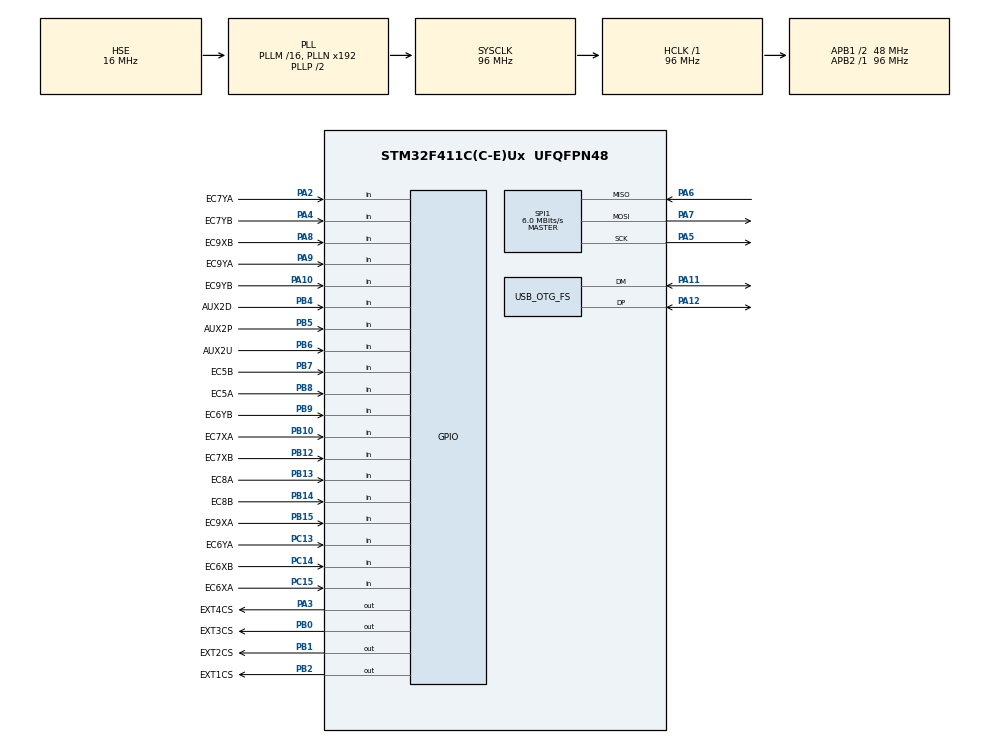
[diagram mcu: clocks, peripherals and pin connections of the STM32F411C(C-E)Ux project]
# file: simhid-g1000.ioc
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Mcu.Family=STM32F4
Mcu.Name=STM32F411C(C-E)Ux
Mcu.Package=UFQFPN48
NVIC.OTG_FS_IRQn=true\:0\:0\:false\:false\:true\:false\:true
NVIC.PriorityGroup=NVIC_PRIORITYGROUP_4
PA10.GPIO_Label=EC9YB
PA10.Signal=GPIO_Input
PA11.Mode=Device_Only
PA11.Signal=USB_OTG_FS_DM
PA12.Mode=Device_Only
PA12.Signal=USB_OTG_FS_DP
PA13.Mode=Serial_Wire
PA13.Signal=SYS_JTMS-SWDIO
PA14.Mode=Serial_Wire
PA14.Signal=SYS_JTCK-SWCLK
PA2.GPIO_Label=EC7YA
PA2.Signal=GPIO_Input
PA3.GPIO_Label=EXT4CS
PA3.PinState=GPIO_PIN_SET
PA3.Signal=GPIO_Output
PA4.GPIO_Label=EC7YB
PA4.Signal=GPIO_Input
PA5.Mode=Full_Duplex_Master
PA5.Signal=SPI1_SCK
PA6.Mode=Full_Duplex_Master
PA6.Signal=SPI1_MISO
PA7.Mode=Full_Duplex_Master
PA7.Signal=SPI1_MOSI
PA8.GPIO_Label=EC9XB
PA8.Signal=GPIO_Input
PA9.GPIO_Label=EC9YA
PA9.Signal=GPIO_Input
PB0.GPIO_Label=EXT3CS
PB0.PinState=GPIO_PIN_SET
PB0.Signal=GPIO_Output
PB1.GPIO_Label=EXT2CS
PB1.PinState=GPIO_PIN_SET
PB1.Signal=GPIO_Output
PB10.GPIO_Label=EC7XA
PB10.Signal=GPIO_Input
PB12.GPIO_Label=EC7XB
PB12.Signal=GPIO_Input
PB13.GPIO_Label=EC8A
PB13.Signal=GPIO_Input
PB14.GPIO_Label=EC8B
PB14.Signal=GPIO_Input
PB15.GPIO_Label=EC9XA
PB15.Signal=GPIO_Input
PB2.GPIO_Label=EXT1CS
PB2.PinState=GPIO_PIN_SET
PB2.Signal=GPIO_Output
PB4.GPIO_Label=AUX2D
PB4.Signal=GPIO_Input
PB5.GPIO_Label=AUX2P
PB5.Signal=GPIO_Input
PB6.GPIO_Label=AUX2U
PB6.Signal=GPIO_Input
PB7.GPIO_Label=EC5B
PB7.Signal=GPIO_Input
PB8.GPIO_Label=EC5A
PB8.Signal=GPIO_Input
PB9.GPIO_Label=EC6YB
PB9.Signal=GPIO_Input
PC13-ANTI_TAMP.GPIO_Label=EC6YA
PC13-ANTI_TAMP.Signal=GPIO_Input
PC14-OSC32_IN.GPIO_Label=EC6XB
PC14-OSC32_IN.Signal=GPIO_Input
PC15-OSC32_OUT.GPIO_Label=EC6XA
PC15-OSC32_OUT.Signal=GPIO_Input
PH0\ -\ OSC_IN.Mode=HSE-External-Oscillator
PH0\ -\ OSC_IN.Signal=RCC_OSC_IN
PH1\ -\ OSC_OUT.Mode=HSE-External-Oscillator
PH1\ -\ OSC_OUT.Signal=RCC_OSC_OUT
ProjectManager.HeapSize=0x200
ProjectManager.StackSize=0x400
ProjectManager.TargetToolchain=Makefile
RCC.AHBFreq_Value=96000000
RCC.APB1CLKDivider=RCC_HCLK_DIV2
RCC.APB1Freq_Value=48000000
RCC.APB1TimFreq_Value=96000000
RCC.APB2Freq_Value=96000000
RCC.APB2TimFreq_Value=96000000
RCC.CortexFreq_Value=96000000
RCC.HCLKFreq_Value=96000000
RCC.HSE_VALUE=16000000
RCC.HSI_VALUE=16000000
RCC.LSE_VALUE=32768
RCC.SYSCLKFreq_VALUE=96000000
RCC.SYSCLKSource=RCC_SYSCLKSOURCE_PLLCLK
RCC.VCOOutputFreq_Value=192000000
SPI1.BaudRatePrescaler=SPI_BAUDRATEPRESCALER_16
SPI1.CalculateBaudRate=6.0 MBits/s
SPI1.Direction=SPI_DIRECTION_2LINES
SPI1.Mode=SPI_MODE_MASTER
SPI1.VirtualType=VM_MASTER
TIM2.AutoReloadPreload=TIM_AUTORELOAD_PRELOAD_ENABLE
TIM2.Period=4294967295
TIM2.Prescaler=47
USB_DEVICE.CLASS_NAME_FS=CDC
USB_DEVICE.MANUFACTURER_STRING=opiopan@gmail.com
USB_DEVICE.PRODUCT_STRING_CDC_FS=SimHID G1000 Virtual ComPort
USB_DEVICE.USBD_SELF_POWERED=0
USB_DEVICE.VirtualMode=Cdc
USB_DEVICE.VirtualModeFS=Cdc_FS
USB_OTG_FS.VirtualMode=Device_Only
VP_TIM2_VS_ClockSourceINT.Mode=Internal
VP_USB_DEVICE_VS_USB_DEVICE_CDC_FS.Mode=CDC_FS
board=custom

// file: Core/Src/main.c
/* USER CODE BEGIN Header */
/**
  ******************************************************************************
  * @file           : main.c
  * @brief          : Main program body
  ******************************************************************************
  * @attention
  *
  * <h2><center>&copy; Copyright (c) 2021 STMicroelectronics.
  * All rights reserved.</center></h2>
  *
  * This software component is licensed by ST under Ultimate Liberty license
  * SLA0044, the "License"; You may not use this file except in compliance with
  * the License. You may obtain a copy of the License at:
  *                             www.st.com/SLA0044
  *
  ******************************************************************************
  */
/* USER CODE END Header */

#include "main.h"
#include "usb_device.h"

/* USER CODE BEGIN Includes */
#include "appmain.h"
/* USER CODE END Includes */

SPI_HandleTypeDef hspi1;

TIM_HandleTypeDef htim2;

void SystemClock_Config(void);
static void MX_GPIO_Init(void);
static void MX_SPI1_Init(void);
static void MX_TIM2_Init(void);

int main(void)
{

  /* MCU Configuration--------------------------------------------------------*/

  /* Reset of all peripherals, Initializes the Flash interface and the Systick. */
  HAL_Init();

  /* Configure the system clock */
  SystemClock_Config();

  /* Initialize all configured peripherals */
  MX_GPIO_Init();
  MX_SPI1_Init();
  MX_USB_DEVICE_Init();
  MX_TIM2_Init();
  /* USER CODE BEGIN 2 */
  APPCONF conf = {
    .hrtimer = &htim2,
    .spi = &hspi1,
  };
  runApp(&conf);
  /* USER CODE END 2 */

  /* Infinite loop */

}

void SystemClock_Config(void)
{
  RCC_OscInitTypeDef RCC_OscInitStruct = {0};
  RCC_ClkInitTypeDef RCC_ClkInitStruct = {0};

  /** Configure the main internal regulator output voltage
  */
  __HAL_RCC_PWR_CLK_ENABLE();
  __HAL_PWR_VOLTAGESCALING_CONFIG(PWR_REGULATOR_VOLTAGE_SCALE1);
  /** Initializes the CPU, AHB and APB busses clocks
  */
  RCC_OscInitStruct.OscillatorType = RCC_OSCILLATORTYPE_HSE;
  RCC_OscInitStruct.HSEState = RCC_HSE_ON;
  RCC_OscInitStruct.PLL.PLLState = RCC_PLL_ON;
  RCC_OscInitStruct.PLL.PLLSource = RCC_PLLSOURCE_HSE;
  RCC_OscInitStruct.PLL.PLLM = 16;
  RCC_OscInitStruct.PLL.PLLN = 192;
  RCC_OscInitStruct.PLL.PLLP = RCC_PLLP_DIV2;
  RCC_OscInitStruct.PLL.PLLQ = 4;
  if (HAL_RCC_OscConfig(&RCC_OscInitStruct) != HAL_OK)
  {
    Error_Handler();
  }
  /** Initializes the CPU, AHB and APB busses clocks
  */
  RCC_ClkInitStruct.ClockType = RCC_CLOCKTYPE_HCLK|RCC_CLOCKTYPE_SYSCLK
                              |RCC_CLOCKTYPE_PCLK1|RCC_CLOCKTYPE_PCLK2;
  RCC_ClkInitStruct.SYSCLKSource = RCC_SYSCLKSOURCE_PLLCLK;
  RCC_ClkInitStruct.AHBCLKDivider = RCC_SYSCLK_DIV1;
  RCC_ClkInitStruct.APB1CLKDivider = RCC_HCLK_DIV2;
  RCC_ClkInitStruct.APB2CLKDivider = RCC_HCLK_DIV1;

  if (HAL_RCC_ClockConfig(&RCC_ClkInitStruct, FLASH_LATENCY_3) != HAL_OK)
  {
    Error_Handler();
  }
}

static void MX_SPI1_Init(void)
{

  /* SPI1 parameter configuration*/
  hspi1.Instance = SPI1;
  hspi1.Init.Mode = SPI_MODE_MASTER;
  hspi1.Init.Direction = SPI_DIRECTION_2LINES;
  hspi1.Init.DataSize = SPI_DATASIZE_8BIT;
  hspi1.Init.CLKPolarity = SPI_POLARITY_LOW;
  hspi1.Init.CLKPhase = SPI_PHASE_1EDGE;
  hspi1.Init.NSS = SPI_NSS_SOFT;
  hspi1.Init.BaudRatePrescaler = SPI_BAUDRATEPRESCALER_16;
  hspi1.Init.FirstBit = SPI_FIRSTBIT_MSB;
  hspi1.Init.TIMode = SPI_TIMODE_DISABLE;
  hspi1.Init.CRCCalculation = SPI_CRCCALCULATION_DISABLE;
  hspi1.Init.CRCPolynomial = 10;
  if (HAL_SPI_Init(&hspi1) != HAL_OK)
  {
    Error_Handler();
  }

}

static void MX_TIM2_Init(void)
{

  TIM_ClockConfigTypeDef sClockSourceConfig = {0};
  TIM_MasterConfigTypeDef sMasterConfig = {0};

  htim2.Instance = TIM2;
  htim2.Init.Prescaler = 47;
  htim2.Init.CounterMode = TIM_COUNTERMODE_UP;
  htim2.Init.Period = 4294967295;
  htim2.Init.ClockDivision = TIM_CLOCKDIVISION_DIV1;
  htim2.Init.AutoReloadPreload = TIM_AUTORELOAD_PRELOAD_ENABLE;
  if (HAL_TIM_Base_Init(&htim2) != HAL_OK)
  {
    Error_Handler();
  }
  sClockSourceConfig.ClockSource = TIM_CLOCKSOURCE_INTERNAL;
  if (HAL_TIM_ConfigClockSource(&htim2, &sClockSourceConfig) != HAL_OK)
  {
    Error_Handler();
  }
  sMasterConfig.MasterOutputTrigger = TIM_TRGO_RESET;
  sMasterConfig.MasterSlaveMode = TIM_MASTERSLAVEMODE_DISABLE;
  if (HAL_TIMEx_MasterConfigSynchronization(&htim2, &sMasterConfig) != HAL_OK)
  {
    Error_Handler();
  }

}

static void MX_GPIO_Init(void)
{
  GPIO_InitTypeDef GPIO_InitStruct = {0};

  /* GPIO Ports Clock Enable */
  __HAL_RCC_GPIOC_CLK_ENABLE();
  __HAL_RCC_GPIOH_CLK_ENABLE();
  __HAL_RCC_GPIOA_CLK_ENABLE();
  __HAL_RCC_GPIOB_CLK_ENABLE();

  /*Configure GPIO pin Output Level */
  HAL_GPIO_WritePin(EXT4CS_GPIO_Port, EXT4CS_Pin, GPIO_PIN_SET);

  /*Configure GPIO pin Output Level */
  HAL_GPIO_WritePin(GPIOB, EXT3CS_Pin|EXT2CS_Pin|EXT1CS_Pin, GPIO_PIN_SET);

  /*Configure GPIO pins : EC6YA_Pin EC6XB_Pin EC6XA_Pin */
  GPIO_InitStruct.Pin = EC6YA_Pin|EC6XB_Pin|EC6XA_Pin;
  GPIO_InitStruct.Mode = GPIO_MODE_INPUT;
  GPIO_InitStruct.Pull = GPIO_NOPULL;
  HAL_GPIO_Init(GPIOC, &GPIO_InitStruct);

  /*Configure GPIO pins : EC7YA_Pin EC7YB_Pin EC9XB_Pin EC9YA_Pin
                           EC9YB_Pin */
  GPIO_InitStruct.Pin = EC7YA_Pin|EC7YB_Pin|EC9XB_Pin|EC9YA_Pin
                          |EC9YB_Pin;
  GPIO_InitStruct.Mode = GPIO_MODE_INPUT;
  GPIO_InitStruct.Pull = GPIO_NOPULL;
  HAL_GPIO_Init(GPIOA, &GPIO_InitStruct);

  /*Configure GPIO pin : EXT4CS_Pin */
  GPIO_InitStruct.Pin = EXT4CS_Pin;
  GPIO_InitStruct.Mode = GPIO_MODE_OUTPUT_PP;
  GPIO_InitStruct.Pull = GPIO_NOPULL;
  GPIO_InitStruct.Speed = GPIO_SPEED_FREQ_LOW;
  HAL_GPIO_Init(EXT4CS_GPIO_Port, &GPIO_InitStruct);

  /*Configure GPIO pins : EXT3CS_Pin EXT2CS_Pin EXT1CS_Pin */
  GPIO_InitStruct.Pin = EXT3CS_Pin|EXT2CS_Pin|EXT1CS_Pin;
  GPIO_InitStruct.Mode = GPIO_MODE_OUTPUT_PP;
  GPIO_InitStruct.Pull = GPIO_NOPULL;
  GPIO_InitStruct.Speed = GPIO_SPEED_FREQ_LOW;
  HAL_GPIO_Init(GPIOB, &GPIO_InitStruct);

  /*Configure GPIO pins : EC7XA_Pin EC7XB_Pin EC8A_Pin EC8B_Pin
                           EC9XA_Pin AUX2D_Pin AUX2P_Pin AUX2U_Pin
                           EC5B_Pin EC5A_Pin EC6YB_Pin */
  GPIO_InitStruct.Pin = EC7XA_Pin|EC7XB_Pin|EC8A_Pin|EC8B_Pin
                          |EC9XA_Pin|AUX2D_Pin|AUX2P_Pin|AUX2U_Pin
                          |EC5B_Pin|EC5A_Pin|EC6YB_Pin;
  GPIO_InitStruct.Mode = GPIO_MODE_INPUT;
  GPIO_InitStruct.Pull = GPIO_NOPULL;
  HAL_GPIO_Init(GPIOB, &GPIO_InitStruct);

}

void Error_Handler(void)
{
}

/************************ (C) COPYRIGHT STMicroelectronics *****END OF FILE****/
